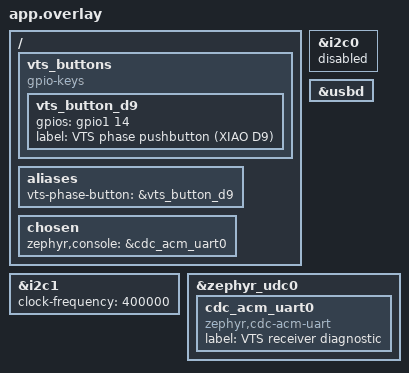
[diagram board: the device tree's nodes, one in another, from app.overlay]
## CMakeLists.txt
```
cmake_minimum_required(VERSION 3.20.0)
find_package(Zephyr REQUIRED HINTS $ENV{ZEPHYR_BASE})
project(da7280_receiver)
target_sources(app PRIVATE src/main.c src/clic.c src/clic_reply.c src/phase_selection.c src/phase_wire.c src/recovery_policy.c src/reconnect_policy.c src/ble_packet.c src/ble_telemetry.c)

# Stage 2: approved FSM and single-owner ESB integration.
target_sources(app PRIVATE src/vts_phase_fsm.c src/vts_phase_controller.c src/vts_phase_link.c src/vts_phase_runtime.c)

# Read-only impedance telemetry; core phase FSM/controller unchanged.
target_sources(app PRIVATE src/vts_impedance.c src/vts_phase_persist.c)

# Read-only v12 payload and immutable snapshot adapter.
target_sources(app PRIVATE src/vts_telemetry_packet.c src/vts_telemetry_snapshot.c)
```

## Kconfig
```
mainmenu "VTS v1.13a Persistent Permanent experimental receiver"
source "Kconfig.zephyr"
config VTS_IMPEDANCE
    bool "Read-only CLIC EEG impedance telemetry"
    default y
    help
      Read status opcode 12 and scale opcode 18 sensor 6 via the existing
      command owner. No change to stimulation settings or phase timer policy.

config VTS_BLE_TELEMETRY
    bool "Experimental read-only BLE advertising telemetry"
    depends on BT && ESB && ESB_MPSL_TIMESLOT
    default n
    help
      Opt in with ble_telemetry.conf. Phase/impedance engine stays the same.
      ESB reception is deliberately unavailable during short advertising windows.

config VTS_BLE_INTERVAL_MS
    int "Minimum interval between advertising-window attempts (ms)"
    depends on VTS_BLE_TELEMETRY
    range 1000 60000
    default 5000

config VTS_BLE_WINDOW_MS
    int "Requested advertising window duration (ms)"
    depends on VTS_BLE_TELEMETRY
    range 30 200
    default 200
```

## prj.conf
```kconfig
CONFIG_I2C=y
CONFIG_FLASH=y
CONFIG_FLASH_MAP=y
CONFIG_NVS=y
CONFIG_LOG=y
CONFIG_ESB=y
CONFIG_BUILD_OUTPUT_UF2=y

CONFIG_GPIO=y

# v1.5 USB CDC ACM diagnostics; mirrors the already tested mock TX USB stack.
CONFIG_SERIAL=y
CONFIG_CONSOLE=y
CONFIG_UART_CONSOLE=y
CONFIG_UART_LINE_CTRL=y
CONFIG_USB_DEVICE_STACK=y
CONFIG_USB_DEVICE_STACK_NEXT=n
CONFIG_USBD_CDC_ACM_CLASS=n
CONFIG_USB_CDC_ACM=y
CONFIG_USB_DEVICE_PRODUCT="VTS v1.8 Phase ESB Test"
CONFIG_LOG_BACKEND_UART=y
CONFIG_LOG_MODE_DEFERRED=y
CONFIG_LOG_BUFFER_SIZE=4096
CONFIG_MAIN_STACK_SIZE=2048
```

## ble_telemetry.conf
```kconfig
# Explicit opt-in: experimental, non-connectable manufacturer advertising.
# The ESB receiver is paused for a requested 200 ms on periodic (~5 s) or
# post-SELECTION_COMMITTED priority windows (only when CLIC/ESB is idle).
# Hardware scheduling/latency must be measured; first bench check: stimulation OFF.
CONFIG_BT=y
CONFIG_BT_PERIPHERAL=y
CONFIG_BT_DEVICE_NAME="VTS-v112-test"
CONFIG_BT_MAX_CONN=1
CONFIG_ESB_MPSL_TIMESLOT=y
CONFIG_MPSL=y
CONFIG_MPSL_TIMESLOT_SESSION_COUNT=1
CONFIG_CLOCK_CONTROL=y
CONFIG_ESB_CLOCK_INIT=y
CONFIG_MAIN_STACK_SIZE=4096
CONFIG_SYSTEM_WORKQUEUE_STACK_SIZE=4096
CONFIG_VTS_BLE_TELEMETRY=y
CONFIG_VTS_BLE_INTERVAL_MS=5000
CONFIG_VTS_BLE_WINDOW_MS=200
```

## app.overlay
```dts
#include <zephyr/dt-bindings/gpio/gpio.h>

&i2c1 {
    status = "okay";
    clock-frequency = <400000>;
};

&i2c0 {
    status = "disabled";
};

&usbd {
    status = "okay";
};
/* Physical pushbutton wired between XIAO D9 (nRF52840 P1.14) and 3.3 V.
 * Released=low, pressed=high. Internal pull-down provides released state.
 */
/ {
    vts_buttons: vts_buttons {
        compatible = "gpio-keys";
        vts_button_d9: vts_button_d9 {
            gpios = <&gpio1 14 (GPIO_ACTIVE_HIGH | GPIO_PULL_DOWN)>;
            label = "VTS phase pushbutton (XIAO D9)";
        };
    };
    aliases {
        vts-phase-button = &vts_button_d9;
    };
};

/* v1.4 diagnostic USB serial console: no change to receiver radio or GPIO.
 * Same legacy CDC-ACM stack/devicetree pattern as tested XIAO mock TX.
 */
/ {
    chosen {
        zephyr,console = &cdc_acm_uart0;
    };
};
&zephyr_udc0 {
    cdc_acm_uart0: cdc_acm_uart0 {
        compatible = "zephyr,cdc-acm-uart";
        label = "VTS receiver diagnostic";
    };
};
```

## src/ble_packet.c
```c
#include "ble_packet.h"
#include <stddef.h>
#include <string.h>

static void write16(uint8_t *out, uint16_t x)
{
    out[0] = (uint8_t)x;
    out[1] = (uint8_t)(x >> 8);
}

static void write32(uint8_t *out, uint32_t x)
{
    for (unsigned i = 0; i < 4U; ++i) {
        out[i] = (uint8_t)(x >> (8U * i));
    }
}

uint16_t vts_ble_packet_crc16(const uint8_t *bytes, unsigned len)
{
    uint16_t crc = 0xffffU;
    for (unsigned i = 0; i < len; ++i) {
        crc ^= (uint16_t)bytes[i] << 8;
        for (unsigned j = 0; j < 8U; ++j) {
            crc = (crc & 0x8000U) ? (uint16_t)((crc << 1) ^ 0x1021U) : (uint16_t)(crc << 1);
        }
    }
    return crc;
}

bool vts_ble_packet_encode(uint8_t out[VTS_BLE_PACKET_SIZE],
                           const struct vts_ble_phase_snapshot *snapshot,
                           uint32_t sequence, uint32_t uptime_ms)
{
    if (out == NULL || snapshot == NULL ||
        snapshot->index_one_based == 0U ||
        snapshot->index_one_based > VTS_BLE_PHASE_COUNT ||
        snapshot->phase_deg < -180 || snapshot->phase_deg > 180 ||
        (snapshot->rejected_mask & 0xf000U) != 0U ||
        (snapshot->accepted_mask & 0xf000U) != 0U) {
        return false;
    }
    memset(out, 0, VTS_BLE_PACKET_SIZE);
    out[0] = VTS_BLE_PACKET_VERSION;
    out[1] = (snapshot->locked ? VTS_BLE_FLAG_LOCKED : 0U) |
             (snapshot->pending ? VTS_BLE_FLAG_PENDING : 0U);
    out[2] = VTS_BLE_PHASE_COUNT;
    out[3] = snapshot->index_one_based;
    write32(out + 4, sequence);
    write32(out + 8, uptime_ms);
    write16(out + 12, snapshot->rejected_mask);
    write16(out + 14, snapshot->accepted_mask);
    write16(out + 16, (uint16_t)snapshot->phase_deg);
    write16(out + 18, vts_ble_packet_crc16(out, 18U));
    return true;
}
```

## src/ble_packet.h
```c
#ifndef VTS_BLE_PACKET_H
#define VTS_BLE_PACKET_H

#include <stdint.h>
#include <stdbool.h>

#define VTS_BLE_PACKET_VERSION 9U
#define VTS_BLE_PACKET_SIZE 20U
#define VTS_BLE_PHASE_COUNT 12U
#define VTS_BLE_FLAG_LOCKED 0x01U
#define VTS_BLE_FLAG_PENDING 0x02U

/* Packet v9, little-endian integers, 20 bytes:
 * [0] protocol 9; [1] flags; [2] count=12; [3] index=1..12
 * [4..7] sequence uint32; [8..11] VTS uptime ms uint32
 * [12..13] rejected history mask u16; [14..15] accepted history mask u16
 * [16..17] confirmed phase signed i16, degrees; [18..19] CRC16-CCITT-FALSE.
 * This is not the colleague's v6 simulated phase protocol.
 */
struct vts_ble_phase_snapshot {
    int16_t phase_deg;
    uint8_t index_one_based;
    uint16_t rejected_mask;
    uint16_t accepted_mask;
    bool locked;
    bool pending;
};

uint16_t vts_ble_packet_crc16(const uint8_t *bytes, unsigned len);
bool vts_ble_packet_encode(uint8_t out[VTS_BLE_PACKET_SIZE],
                           const struct vts_ble_phase_snapshot *snapshot,
                           uint32_t sequence, uint32_t uptime_ms);

#endif
```

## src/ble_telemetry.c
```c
/* v1.12a BENCH ONLY: bounded advertising windows, same radio as CLIC ESB.
 * Preserves v1.9a's proven-on-phone legacy advertising/MPSL approach, now
 * coordinated by the SINGLE main-thread ESB owner. Not a claim of lossless
 * concurrent stimulation: ESB cannot receive during the advertising window.
 */
#include "ble_telemetry.h"
#if defined(CONFIG_BT)
#if !defined(CONFIG_VTS_BLE_TELEMETRY) || !defined(CONFIG_ESB_MPSL_TIMESLOT)
#error "Use ble_telemetry.conf: explicit telemetry and MPSL are required"
#endif
#include <zephyr/kernel.h>
#include <zephyr/bluetooth/bluetooth.h>
#include <zephyr/bluetooth/hci.h>
#include <zephyr/logging/log.h>
#include <esb.h>
#include <errno.h>
#include <string.h>
LOG_MODULE_REGISTER(vts_ble, LOG_LEVEL_INF);
BUILD_ASSERT(CONFIG_VTS_BLE_WINDOW_MS < 1000, "Window must be shorter than link inactivity grace");
BUILD_ASSERT(3U+2U+2U+VTS_TELEMETRY_BYTES == 31U, "Legacy advertising payload must fit 31 bytes");
static bool ready, advertising, radio_failed, telemetry_disabled, priority_pending;
static bool startup_first_pending, startup_followup_pending;
static uint64_t startup_followup_due_ms;
#define VTS_BLE_STARTUP_SECOND_MS 850U
static uint64_t next_ms, stop_ms, pause_ms, retry_after_ms;
/* A transient ESB pause contention must not spin every 10 ms. */
#define VTS_BLE_PRIORITY_RETRY_MS 100U
static uint16_t sequence;
static uint8_t manufacturer[2U+VTS_TELEMETRY_BYTES];
static void fatal_radio(const char *stage,int rc)
{
    radio_failed=true;telemetry_disabled=true;
    /* Do not later restart ESB behind a terminal FSM conflict/fault. */
    LOG_ERR("VTS_BLE RADIO_FAULT stage=%s rc=%d reset_required=1",stage,rc);
}
static bool resume_esb(void)
{
    int rc=esb_start_rx();
    if(rc!=0 && rc!=-EALREADY){fatal_radio("ESB_RESUME",rc);return false;}
    LOG_INF("VTS_BLE ESB_RESUMED seq=%u gap_ms=%llu",(unsigned int)sequence,
            (unsigned long long)((uint64_t)k_uptime_get()-pause_ms));
    return true;
}
int vts_ble_telemetry_init(void)
{
    ready=false;advertising=false;radio_failed=false;telemetry_disabled=false;
    priority_pending=false;retry_after_ms=0;sequence=0;
    startup_first_pending=false;startup_followup_pending=false;startup_followup_due_ms=0;
    int rc=bt_enable(NULL);if(rc!=0)return rc;
    ready=true;next_ms=(uint64_t)k_uptime_get()+CONFIG_VTS_BLE_INTERVAL_MS;
    LOG_INF("VTS_BLE READY protocol=%u interval_ms=%u window_ms=%u advertise_only=1 legacy_app_compatible=0",
        (unsigned int)VTS_TELEMETRY_VERSION,
        (unsigned int)CONFIG_VTS_BLE_INTERVAL_MS,(unsigned int)CONFIG_VTS_BLE_WINDOW_MS);
    return 0;
}
bool vts_ble_telemetry_busy(void){return advertising;}
bool vts_ble_telemetry_failed(void){return radio_failed;}
void vts_ble_telemetry_request_priority(void)
{
    if (!ready || telemetry_disabled || radio_failed) return;
    /* Coalesce repeated requests. Never call BLE or ESB APIs from this path. */
    priority_pending=true;
    LOG_INF("VTS_BLE PRIORITY_REQUEST t_ms=%llu",(unsigned long long)k_uptime_get());
}
void vts_ble_telemetry_request_startup_sync(void)
{
    if (!ready || telemetry_disabled || radio_failed) return;
    /* The caller is the single phase owner after CLIC has GET/SET/GET-verified
     * startup/restored Permanent. Do not perform any radio operation here. */
    startup_first_pending=true;
    startup_followup_pending=false;
    priority_pending=true;
    LOG_INF("VTS_BLE STARTUP_SYNC_REQUEST t_ms=%llu",(unsigned long long)k_uptime_get());
}
bool vts_ble_telemetry_due(uint64_t now)
{
    return ready && !telemetry_disabled && !advertising &&
        now>=retry_after_ms && (priority_pending ||
        (startup_followup_pending && now>=startup_followup_due_ms) || now>=next_ms);
}
void vts_ble_telemetry_service(bool abort_window,uint64_t now)
{
    if(!advertising || radio_failed || (!abort_window && now<stop_ms))return;
    int rc=bt_le_adv_stop();
    if(rc!=0 && rc!=-EALREADY){
        fatal_radio("ADV_STOP",rc);
        /* No unconditional ESB resume when BLE stop failed. The owner will
         * latch FAULT, stop ESB and require explicit reset. */
        return;
    }
    advertising=false;
    (void)resume_esb();
}
void vts_ble_telemetry_poll(const vts_telemetry_packet_t *snapshot,
                           bool allowed,uint64_t now,bool (*recheck)(void))
{
    if(!allowed || !snapshot || !recheck || !vts_ble_telemetry_due(now))return;
    const bool second_due=startup_followup_pending && now>=startup_followup_due_ms;
    const bool priority=priority_pending || second_due;
    const bool first_sync=startup_first_pending && priority_pending;
    vts_telemetry_packet_t s=*snapshot;s.sequence=(uint16_t)(sequence+1U);
    uint8_t b[VTS_TELEMETRY_BYTES];
    if(!vts_telemetry_encode(b,&s)){
        telemetry_disabled=true;LOG_ERR("VTS_BLE INVALID_SNAPSHOT telemetry_disabled=1");return;
    }
    /* Retry pause contention later; never discard a pending ACK payload. */
    next_ms=now+CONFIG_VTS_BLE_INTERVAL_MS;
    int rc=esb_stop_rx();
    if(rc!=0){
        if(priority)retry_after_ms=now+VTS_BLE_PRIORITY_RETRY_MS;
        LOG_WRN("VTS_BLE ESB_PAUSE_SKIPPED rc=%d",rc);return;
    }
    pause_ms=(uint64_t)k_uptime_get();
    if(!recheck()){
        if(priority)retry_after_ms=now+VTS_BLE_PRIORITY_RETRY_MS;
        LOG_INF("VTS_BLE WINDOW_ABORTED input_or_busy=1");
        (void)resume_esb();return;
    }
    manufacturer[0]=0xffU;manufacturer[1]=0xffU;
    memcpy(manufacturer+2,b,sizeof(b));
    const struct bt_data ad[]={
        BT_DATA_BYTES(BT_DATA_FLAGS,BT_LE_AD_NO_BREDR),
        BT_DATA(BT_DATA_MANUFACTURER_DATA,manufacturer,sizeof(manufacturer))};
    const struct bt_le_adv_param p=BT_LE_ADV_PARAM_INIT(
        BT_LE_ADV_OPT_USE_IDENTITY,BT_GAP_ADV_FAST_INT_MIN_1,BT_GAP_ADV_FAST_INT_MIN_1,NULL);
    rc=bt_le_adv_start(&p,ad,ARRAY_SIZE(ad),NULL,0);
    if(rc!=0){
        LOG_ERR("VTS_BLE ADV_START_FAILED rc=%d telemetry_disabled=1",rc);
        telemetry_disabled=true;(void)resume_esb();return;
    }
    advertising=true;sequence=s.sequence;
    priority_pending=false;retry_after_ms=0;
    if (first_sync) {
        startup_first_pending=false;
        startup_followup_pending=true;
        startup_followup_due_ms=pause_ms+VTS_BLE_STARTUP_SECOND_MS;
    } else if (second_due) {
        startup_followup_pending=false;
    }
    stop_ms=pause_ms+CONFIG_VTS_BLE_WINDOW_MS;
    LOG_INF("VTS_BLE ADV_START seq=%u phase=%d index=%u fine_parent=%u elapsed_s=%u rejected=0x%03X tested=0x%03X permanent=0x%03X imp_state=%u imp_kohm=%u window_ms=%u priority=%u startup_sync=%u",
        (unsigned int)sequence,(int)s.phase_deg,(unsigned int)s.index_one_based,
        (unsigned int)s.fine_parent_one_based,(unsigned int)s.elapsed_seconds,(unsigned int)s.rejected_mask,(unsigned int)s.tested_mask,
        (unsigned int)s.permanent_mask,(unsigned int)s.impedance_state,
        (unsigned int)s.impedance_kohm,(unsigned int)CONFIG_VTS_BLE_WINDOW_MS,priority ? 1U : 0U,
        first_sync ? 1U : (second_due ? 2U : 0U));
    /* One line per advertising window, never per EEG/stimulation packet.
     * This is the offered payload, NOT evidence that a phone received it. */
    char hex[2U*VTS_TELEMETRY_BYTES+1U];static const char digits[]="0123456789ABCDEF";
    for(unsigned i=0;i<VTS_TELEMETRY_BYTES;++i){hex[2*i]=digits[b[i]>>4];hex[2*i+1]=digits[b[i]&15U];}
    hex[sizeof(hex)-1U]='\0';
    LOG_INF("VTS_BLE PAYLOAD seq=%u hex=%s",(unsigned int)sequence,hex);
}
#else
int vts_ble_telemetry_init(void){return 0;}
bool vts_ble_telemetry_busy(void){return false;}
bool vts_ble_telemetry_failed(void){return false;}
bool vts_ble_telemetry_due(uint64_t now){(void)now;return false;}
void vts_ble_telemetry_request_priority(void){}
void vts_ble_telemetry_request_startup_sync(void){}
void vts_ble_telemetry_service(bool abort_window,uint64_t now){(void)abort_window;(void)now;}
void vts_ble_telemetry_poll(const vts_telemetry_packet_t *s,bool a,uint64_t n,bool(*r)(void))
{(void)s;(void)a;(void)n;(void)r;}
#endif
```

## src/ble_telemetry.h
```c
#ifndef VTS_BLE_TELEMETRY_H
#define VTS_BLE_TELEMETRY_H
#include "vts_telemetry_packet.h"
#include <stdint.h>
#include <stdbool.h>
/* All functions are called by main (the existing single ESB owner), never
 * from an ISR or system-workqueue callback. No commands from the phone. */
int vts_ble_telemetry_init(void);
bool vts_ble_telemetry_busy(void);
bool vts_ble_telemetry_failed(void);
bool vts_ble_telemetry_due(uint64_t now_ms);
/* Request a prompt post-commit snapshot. Only the main ESB owner services it;
 * a request never interrupts an in-flight CLIC command or BLE window. */
void vts_ble_telemetry_request_priority(void);
/* Two guarded snapshots spaced ~850 ms after confirmed startup or restore.
 * They corroborate a reset sequence counter without altering v12 payloads. */
void vts_ble_telemetry_request_startup_sync(void);
/* Finish a window when due, or early for a queued input/button/fault. */
void vts_ble_telemetry_service(bool abort_window, uint64_t now_ms);
/* recheck runs after ESB stops, to close the last IRQ/guard race. */
void vts_ble_telemetry_poll(const vts_telemetry_packet_t *snapshot,
                           bool allowed, uint64_t now_ms, bool (*recheck)(void));
#endif
```

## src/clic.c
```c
/* Adapted from Huru's nRF5 API example to nRF Connect SDK / Zephyr ESB. */
#include <stdint.h>
#include <errno.h>
#include <string.h>
#include <zephyr/logging/log.h>
#include <esb.h>
#include "clic.h"
#include "phase_wire.h"

LOG_MODULE_DECLARE(esb_prx_da7280);

void clic_process_response(const uint8_t *response, uint32_t length)
{
    /* Response body semantics remain undocumented; do not assume success. */
    LOG_HEXDUMP_INF(response, length, "CLIC command response (raw)");
}

/* Port of Rob's generic five-byte command sender to Zephyr ESB.
 * esb_write_payload() on a PRX queues an ACK payload. The PTX bridge
 * must send an ACK-requesting packet to retrieve and forward the command.
 */
int clic_send_command(const uint8_t command[CLIC_CMD_BODY_BYTES])
{
    if (command == NULL) {
        return -EINVAL;
    }
    struct esb_payload tx = {0};
    tx.pipe = ESB_PIPE_VTS;
    tx.length = (uint8_t)(sizeof(esb_packet_header_t) + CLIC_CMD_BODY_BYTES);
    tx.data[0] = (uint8_t)esb_payload_command;
    tx.data[1] = (uint8_t)CLIC_CMD_BODY_BYTES;
    memcpy(&tx.data[sizeof(esb_packet_header_t)], command, CLIC_CMD_BODY_BYTES);

    int err = esb_write_payload(&tx);
    if (err) {
        LOG_ERR("Cannot queue CLIC opcode %u in ESB ACK FIFO: %d", command[0], err);
    } else {
        LOG_INF("Queued CLIC opcode %u in ESB ACK FIFO", command[0]);
    }
    return err;
}

/* Signed int32 degrees. The pure helper is independently host-tested. */
int clic_send_phase(int32_t phase_deg)
{
    uint8_t command[CLIC_CMD_BODY_BYTES];
    if (!vts_pack_set_phase(phase_deg, command)) return -ERANGE;
    return clic_send_command(command);
}

int clic_get_phase(void)
{
    uint8_t command[CLIC_CMD_BODY_BYTES];
    vts_pack_get_phase(command);
    return clic_send_command(command);
}

/* Unsigned 32-bit big-endian frequency in Hz: exactly matches the supplied
 * Python app's struct.pack('>I', oscilltrack_frequency) for opcode 28.
 * This test build permits only 10 or 40 Hz.
 */
int clic_send_frequency(uint32_t frequency_hz)
{
    if (frequency_hz != 10U && frequency_hz != 40U) {
        return -ERANGE;
    }

    const uint8_t command[CLIC_CMD_BODY_BYTES] = {
        (uint8_t)PT10_CMD_SET_OSCILLTRACK_FREQUENCY,
        (uint8_t)((frequency_hz >> 24) & 0xFFU),
        (uint8_t)((frequency_hz >> 16) & 0xFFU),
        (uint8_t)((frequency_hz >> 8) & 0xFFU),
        (uint8_t)(frequency_hz & 0xFFU),
    };
    return clic_send_command(command);
}

/* Legacy read-only frequency GET helper (not used in v1.8 phase mode). */
int clic_get_frequency(void)
{
    const uint8_t command[CLIC_CMD_BODY_BYTES] = {
        (uint8_t)PT10_CMD_GET_OSCILLTRACK_FREQUENCY, 0, 0, 0, 0
    };
    return clic_send_command(command);
}
```

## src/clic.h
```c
#ifndef CLIC_H_INCLUDED
#define CLIC_H_INCLUDED


#include <stdint.h>

typedef enum {
    PT10_CMD_GET_OSCILLTRACK_FREQUENCY = 27,
    PT10_CMD_SET_OSCILLTRACK_FREQUENCY = 28,
    PT10_CMD_GET_OSCILLTRACK_TRIGGER_PHASE = 29,
    PT10_CMD_SET_OSCILLTRACK_TRIGGER_PHASE = 30,
    PT10_CMD_GET_OSCILLTRACK_SUPPRESSION_DUTY_CYCLE = 31,
    PT10_CMD_SET_OSCILLTRACK_SUPPRESSION_DUTY_CYCLE = 32,
    PT10_CMD_STORE_OSCILLTRACK_PARAMETERS = 33,
    PT10_CMD_GET_OSCILLTRACK_FLAGS = 34,
    PT10_CMD_SET_OSCILLTRACK_FLAGS = 35,
    PT10_CMD_GET_CONVERGENCE_GAIN = 36,
    PT10_CMD_SET_CONVERGENCE_GAIN = 37,
    PT10_CMD_CONFIGURE_VTS_HAPTIC = 38,
    PT10_CMD_CONFIGURE_VTS_SLEEP = 39,
} pt10_command_e;

typedef enum {
    esb_payload_command = 1,
    esb_payload_command_response = 2,
    esb_payload_oscilltrack_data = 3,
    esb_payload_timeout = 4,
    esb_payload_ping = 5,
    esb_payload_ping_response = 6,
    esb_payload_bridge_command = 7,
    esb_payload_vts_command = 8,
    esb_payload_stimulus = 9,
    esb_payload_eeg_sample = 10,
} esb_payload_type_e;

#define ESB_PIPE_VTS (0)
typedef struct __attribute__ ((__packed__)) {
    uint8_t payload_type;
    uint8_t payload_length;
} esb_packet_header_t;

/* CLIC command body: exactly 5 opaque bytes, opcode + 4 parameter bytes.
 * The caller packs parameters according to each command's wire format.
 * For OSCILLTRACK_TRIGGER_PHASE, this is signed 32-bit big-endian degrees.
 */
#define CLIC_CMD_PARAMETER_BYTES 4U
#define CLIC_CMD_BODY_BYTES (1U + CLIC_CMD_PARAMETER_BYTES)

void clic_process_response(const uint8_t *response, uint32_t length);
/* Packet transport: command[0..4] already encoded; does not reinterpret bytes. */
int clic_send_command(const uint8_t command[CLIC_CMD_BODY_BYTES]);
/* Opcode 30; phase must be in [-180, +180] whole degrees. */
int clic_send_phase(int32_t phase_deg);
/* Opcode 29: signed 32-bit big-endian phase readback, no mutation. */
int clic_get_phase(void);
/* Opcode 28: frequency in Hz encoded as unsigned 32-bit big-endian.
 * This frequency-test build accepts only 10 or 40 Hz.
 */
int clic_send_frequency(uint32_t frequency_hz);
/* Opcode 27: read-only GET with zero parameter (does not change CLIC). */
int clic_get_frequency(void);

#endif /* CLIC_H_INCLUDED */
```

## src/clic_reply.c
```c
#include "clic_reply.h"

bool vts_clic_reply_decode(const uint8_t *body, size_t length,
                           uint8_t *opcode, uint32_t *be_parameter)
{
    if (body == NULL || opcode == NULL || be_parameter == NULL ||
        length != VTS_CLIC_REPLY_BODY_BYTES) {
        return false;
    }
    *opcode = body[0];
    *be_parameter = ((uint32_t)body[1] << 24) |
                    ((uint32_t)body[2] << 16) |
                    ((uint32_t)body[3] << 8) |
                    (uint32_t)body[4];
    return true;
}
```

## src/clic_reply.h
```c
#ifndef VTS_CLIC_REPLY_H_INCLUDED
#define VTS_CLIC_REPLY_H_INCLUDED
#include <stdbool.h>
#include <stddef.h>
#include <stdint.h>

/* These are application payload bytes AFTER the 2-byte ESB header.
 * Python monitor v5.1 expects opcode + 4 parameter bytes for command responses.
 */
#define VTS_CLIC_REPLY_BODY_BYTES 5U
bool vts_clic_reply_decode(const uint8_t *body, size_t length,
                           uint8_t *opcode, uint32_t *be_parameter);
#endif
```

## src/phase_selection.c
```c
#include "phase_selection.h"

static const int32_t phases[VTS_PHASE_COUNT] = {
    -60, 120, 0, 180, 60, -120, -90, 90, -30, 150, 30, -150
};
static uint8_t current_index;
static bool accepted;
static uint16_t rejected_mask;
static uint16_t accepted_mask;

bool phase_selection_values_valid(void)
{
    static const int32_t reference[VTS_PHASE_COUNT] = {
        -60, 120, 0, 180, 60, -120, -90, 90, -30, 150, 30, -150
    };
    for (uint8_t i = 0; i < VTS_PHASE_COUNT; i++) {
        if (phases[i] != reference[i] || phases[i] < -180 || phases[i] > 180) {
            return false;
        }
        for (uint8_t j = 0; j < i; j++) {
            if (phases[i] == phases[j]) return false;
        }
    }
    return true;
}

void phase_selection_reset(void)
{
    current_index = 0;
    accepted = false;
    rejected_mask = 0;
    accepted_mask = 0;
}
int32_t phase_selection_current(void) { return phases[current_index]; }
int32_t phase_selection_next(void) { return phases[(current_index + 1U) % VTS_PHASE_COUNT]; }
uint8_t phase_selection_index(void) { return current_index; }
bool phase_selection_is_accepted(void) { return accepted; }
uint16_t phase_selection_rejected_mask(void) { return rejected_mask; }
uint16_t phase_selection_accepted_mask(void) { return accepted_mask; }
bool phase_selection_contains(int32_t phase_deg)
{
    for (uint8_t i = 0; i < VTS_PHASE_COUNT; i++) {
        if (phases[i] == phase_deg) return true;
    }
    return false;
}
/* A short press rejects the currently confirmed phase and advances one step.
 * The phase remains in the circular list; the mask is only history for BLE.
 */
bool phase_selection_commit_advance(int32_t confirmed_next_phase)
{
    if (accepted || confirmed_next_phase != phase_selection_next()) return false;
    rejected_mask |= (uint16_t)(1U << current_index);
    current_index = (uint8_t)((current_index + 1U) % VTS_PHASE_COUNT);
    return true;
}
/* A long press accepts the currently confirmed phase and locks until reboot. */
bool phase_selection_accept_current(void)
{
    if (accepted) return false;
    accepted_mask |= (uint16_t)(1U << current_index);
    accepted = true;
    return true;
}
```

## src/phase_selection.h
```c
#ifndef VTS_PHASE_SELECTION_H
#define VTS_PHASE_SELECTION_H
#include <stdbool.h>
#include <stdint.h>

/* User-approved fixed circular order. Indices and angles never disappear. */
#define VTS_PHASE_COUNT 12U
void phase_selection_reset(void);
bool phase_selection_values_valid(void);
int32_t phase_selection_current(void);
int32_t phase_selection_next(void);
uint8_t phase_selection_index(void);
bool phase_selection_contains(int32_t phase_deg);
bool phase_selection_is_accepted(void);
uint16_t phase_selection_rejected_mask(void);
uint16_t phase_selection_accepted_mask(void);
/* These mutate the decision state ONLY after CLIC confirmation and feedback. */
bool phase_selection_commit_advance(int32_t confirmed_next_phase);
bool phase_selection_accept_current(void);
#endif
```

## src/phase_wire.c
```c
#include "phase_wire.h"

bool vts_pack_set_phase(int32_t degrees, uint8_t body[5])
{
    if (body == 0 || degrees < -180 || degrees > 180) return false;
    uint32_t v = (uint32_t)degrees;
    body[0] = 30;
    body[1] = (uint8_t)(v >> 24);
    body[2] = (uint8_t)(v >> 16);
    body[3] = (uint8_t)(v >> 8);
    body[4] = (uint8_t)v;
    return true;
}
void vts_pack_get_phase(uint8_t body[5])
{
    if (body == 0) return;
    body[0] = 29;
    body[1] = 0; body[2] = 0; body[3] = 0; body[4] = 0;
}
int32_t vts_decode_phase_parameter(uint32_t raw)
{
    /* Sign-convert without implementation-defined out-of-range unsigned cast. */
    int64_t signed_value = (raw & UINT32_C(0x80000000)) ?
        ((int64_t)raw - INT64_C(4294967296)) : (int64_t)raw;
    return (int32_t)signed_value;
}
```

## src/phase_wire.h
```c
#ifndef VTS_PHASE_WIRE_H
#define VTS_PHASE_WIRE_H
#include <stdbool.h>
#include <stdint.h>
/* Pure protocol helpers: 5-byte CLIC body, signed big-endian degrees. */
bool vts_pack_set_phase(int32_t degrees, uint8_t body[5]);
void vts_pack_get_phase(uint8_t body[5]);
int32_t vts_decode_phase_parameter(uint32_t be_raw);
#endif
```
